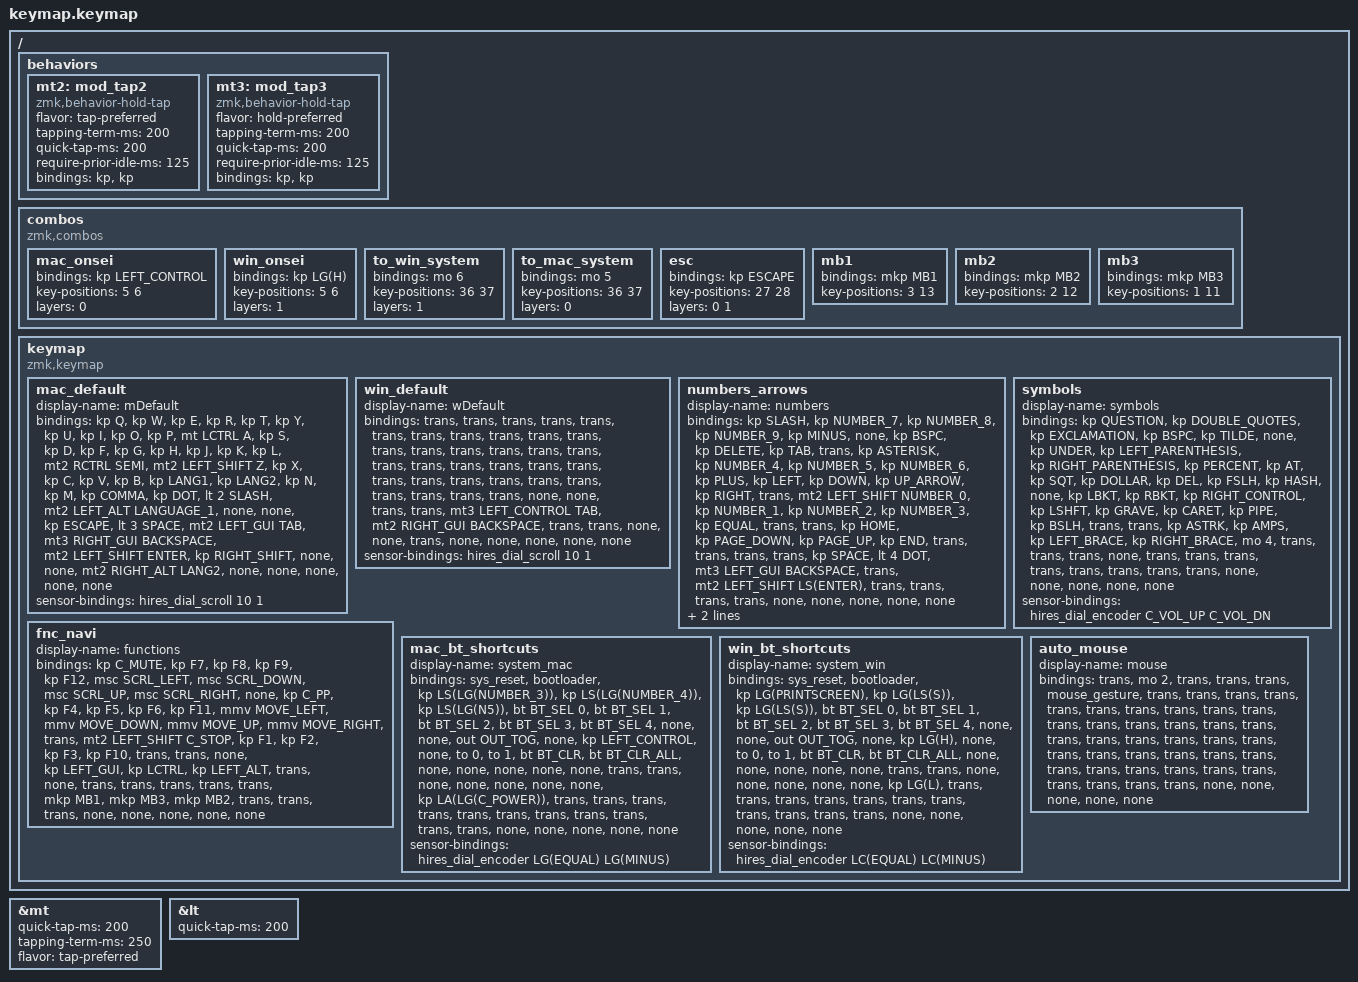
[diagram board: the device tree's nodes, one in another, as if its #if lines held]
/*
 * LisM キーマップを torabo-tsuki LP の S 配列へ移したもの。
 * 位置は size_s_transform の並び（上段10、中段10、下段12、親指12）。
 * 下段の内側2キー（B と N の間）は LisM に無いので &none。
 * ハイレゾダイヤルは LisM のエンコーダに対応する。
 */

#include <behaviors.dtsi>
#include <dt-bindings/zmk/bt.h>
#include <dt-bindings/zmk/keys.h>
#include <dt-bindings/zmk/outputs.h>
#include <dt-bindings/zmk/pointing.h>
#include <mouse-gesture.dtsi>

#if defined(TORABO_TSUKI_LP_INPUT_HIRES_DIAL)
#include <behaviors/hires_dial.dtsi>
#endif

&mt {
    quick-tap-ms = <200>;
    tapping-term-ms = <250>;
    flavor = "tap-preferred";
};

&lt { quick-tap-ms = <200>; };

/ {
    behaviors {
        mt2: mod_tap2 {
            compatible = "zmk,behavior-hold-tap";
            #binding-cells = <2>;
            flavor = "tap-preferred";
            tapping-term-ms = <200>;
            quick-tap-ms = <200>;
            require-prior-idle-ms = <125>;
            bindings = <&kp>, <&kp>;
        };

        mt3: mod_tap3 {
            compatible = "zmk,behavior-hold-tap";
            #binding-cells = <2>;
            flavor = "hold-preferred";
            tapping-term-ms = <200>;
            quick-tap-ms = <200>;
            require-prior-idle-ms = <125>;
            bindings = <&kp>, <&kp>;
        };
    };

    combos {
        compatible = "zmk,combos";

        mac_onsei {
            bindings = <&kp LEFT_CONTROL>;
            key-positions = <5 6>;
            layers = <0>;
        };

        win_onsei {
            bindings = <&kp LG(H)>;
            key-positions = <5 6>;
            layers = <1>;
        };

        to_win_system {
            bindings = <&mo 6>;
            key-positions = <36 37>;
            layers = <1>;
        };

        to_mac_system {
            bindings = <&mo 5>;
            key-positions = <36 37>;
            layers = <0>;
        };

        esc {
            bindings = <&kp ESCAPE>;
            key-positions = <27 28>;
            layers = <0 1>;
        };

        mb1 {
            bindings = <&mkp MB1>;
            key-positions = <3 13>;
        };

        mb2 {
            bindings = <&mkp MB2>;
            key-positions = <2 12>;
        };

        mb3 {
            bindings = <&mkp MB3>;
            key-positions = <1 11>;
        };
    };

    keymap {
        compatible = "zmk,keymap";

        mac_default {
            display-name = "mDefault";
            bindings = <
&kp Q              &kp W  &kp E      &kp R      &kp T        &kp Y                 &kp U            &kp I      &kp O   &kp P
&mt LCTRL A        &kp S  &kp D      &kp F      &kp G        &kp H                 &kp J            &kp K      &kp L   &mt2 RCTRL SEMI
&mt2 LEFT_SHIFT Z  &kp X  &kp C      &kp V      &kp B        &kp LANG1             &kp LANG2         &kp N      &kp M   &kp COMMA  &kp DOT  &lt 2 SLASH
&mt2 LEFT_ALT LANGUAGE_1  &none  &none  &kp ESCAPE  &lt 3 SPACE  &mt2 LEFT_GUI TAB  &mt3 RIGHT_GUI BACKSPACE  &mt2 LEFT_SHIFT ENTER  &kp RIGHT_SHIFT  &none  &none  &mt2 RIGHT_ALT LANG2
#if defined(TORABO_TSUKI_LP_KSCAN_4_DIRECTION_SWITCH)
&none &none &none &none &none
#elif defined(TORABO_TSUKI_LP_INPUT_HIRES_DIAL)
&to 1
#endif
            >;
        };

        win_default {
            display-name = "wDefault";
            bindings = <
&trans  &trans  &trans  &trans  &trans   &trans  &trans  &trans  &trans  &trans
&trans  &trans  &trans  &trans  &trans   &trans  &trans  &trans  &trans  &trans
&trans  &trans  &trans  &trans  &trans   &trans  &trans  &trans  &trans  &trans  &trans  &trans
&trans  &none   &none   &trans  &trans   &mt3 LEFT_CONTROL TAB  &mt2 RIGHT_GUI BACKSPACE  &trans  &trans  &none  &none  &trans
#if defined(TORABO_TSUKI_LP_KSCAN_4_DIRECTION_SWITCH)
&none &none &none &none &none
#elif defined(TORABO_TSUKI_LP_INPUT_HIRES_DIAL)
&to 0
#endif
            >;
        };

        numbers_arrows {
            display-name = "numbers";
            bindings = <
&kp SLASH                 &kp NUMBER_7  &kp NUMBER_8  &kp NUMBER_9  &kp MINUS        &none      &kp BSPC       &kp DELETE    &kp TAB    &trans
&kp ASTERISK              &kp NUMBER_4  &kp NUMBER_5  &kp NUMBER_6  &kp PLUS         &kp LEFT   &kp DOWN       &kp UP_ARROW  &kp RIGHT  &trans
&mt2 LEFT_SHIFT NUMBER_0  &kp NUMBER_1  &kp NUMBER_2  &kp NUMBER_3  &kp EQUAL        &trans     &trans         &kp HOME      &kp PAGE_DOWN  &kp PAGE_UP  &kp END  &trans
&trans                    &trans        &trans        &kp SPACE     &lt 4 DOT        &mt3 LEFT_GUI BACKSPACE  &trans  &mt2 LEFT_SHIFT LS(ENTER)  &trans  &trans  &trans  &trans
#if defined(TORABO_TSUKI_LP_KSCAN_4_DIRECTION_SWITCH)
&none &none &none &none &none
#elif defined(TORABO_TSUKI_LP_INPUT_HIRES_DIAL)
&kp C_MUTE
#endif
            >;
        };

        symbols {
            display-name = "symbols";
            bindings = <
&kp QUESTION  &kp DOUBLE_QUOTES  &kp EXCLAMATION  &kp BSPC  &kp TILDE      &none     &kp UNDER  &kp LEFT_PARENTHESIS  &kp RIGHT_PARENTHESIS  &kp PERCENT
&kp AT        &kp SQT            &kp DOLLAR       &kp DEL   &kp FSLH       &kp HASH  &none      &kp LBKT              &kp RBKT   &kp RIGHT_CONTROL
&kp LSHFT     &kp GRAVE          &kp CARET        &kp PIPE  &kp BSLH       &trans    &trans     &kp ASTRK             &kp AMPS     &kp LEFT_BRACE  &kp RIGHT_BRACE  &mo 4
&trans        &trans             &trans           &none     &trans         &trans    &trans     &trans                &trans       &trans          &trans       &trans
#if defined(TORABO_TSUKI_LP_KSCAN_4_DIRECTION_SWITCH)
&none &none &none &none &none
#elif defined(TORABO_TSUKI_LP_INPUT_HIRES_DIAL)
&kp C_MUTE
#endif
            >;
        };

        fnc_navi {
            display-name = "functions";
            bindings = <
&kp C_MUTE              &kp F7  &kp F8  &kp F9  &kp F12      &msc SCRL_LEFT  &msc SCRL_DOWN  &msc SCRL_UP  &msc SCRL_RIGHT  &none
&kp C_PP                &kp F4  &kp F5  &kp F6  &kp F11      &mmv MOVE_LEFT  &mmv MOVE_DOWN  &mmv MOVE_UP  &mmv MOVE_RIGHT  &trans
&mt2 LEFT_SHIFT C_STOP  &kp F1  &kp F2  &kp F3  &kp F10      &trans          &trans          &none         &kp LEFT_GUI     &kp LCTRL  &kp LEFT_ALT  &trans
&none                   &trans  &trans  &trans  &trans       &trans          &mkp MB1        &mkp MB3      &mkp MB2         &trans     &trans        &trans
#if defined(TORABO_TSUKI_LP_KSCAN_4_DIRECTION_SWITCH)
&none &none &none &none &none
#elif defined(TORABO_TSUKI_LP_INPUT_HIRES_DIAL)
&none
#endif
            >;
        };

        mac_bt_shortcuts {
            display-name = "system_mac";
            bindings = <
&sys_reset           &bootloader  &kp LS(LG(NUMBER_3))  &kp LS(LG(NUMBER_4))  &kp LS(LG(N5))   &bt BT_SEL 0  &bt BT_SEL 1  &bt BT_SEL 2  &bt BT_SEL 3  &bt BT_SEL 4
&none                &none        &out OUT_TOG          &none                 &kp LEFT_CONTROL &none         &to 0         &to 1         &bt BT_CLR    &bt BT_CLR_ALL
&none                &none        &none                 &none                 &none            &trans        &trans        &none         &none         &none         &none  &none
&kp LA(LG(C_POWER))  &trans       &trans                &trans                &trans           &trans        &trans        &trans        &trans        &trans        &trans &trans
#if defined(TORABO_TSUKI_LP_KSCAN_4_DIRECTION_SWITCH)
&none &none &none &none &none
#elif defined(TORABO_TSUKI_LP_INPUT_HIRES_DIAL)
&none
#endif
            >;
        };

        win_bt_shortcuts {
            display-name = "system_win";
            bindings = <
&sys_reset  &bootloader  &kp LG(PRINTSCREEN)  &kp LG(LS(S))  &kp LG(LS(S))   &bt BT_SEL 0  &bt BT_SEL 1  &bt BT_SEL 2  &bt BT_SEL 3  &bt BT_SEL 4
&none       &none        &out OUT_TOG         &none          &kp LG(H)       &none         &to 0         &to 1         &bt BT_CLR    &bt BT_CLR_ALL
&none       &none        &none                &none          &none           &trans        &trans        &none         &none         &none         &none  &none
&kp LG(L)   &trans       &trans               &trans         &trans          &trans        &trans        &trans        &trans        &trans        &trans &trans
#if defined(TORABO_TSUKI_LP_KSCAN_4_DIRECTION_SWITCH)
&none &none &none &none &none
#elif defined(TORABO_TSUKI_LP_INPUT_HIRES_DIAL)
&none
#endif
            >;
        };

        auto_mouse {
            display-name = "mouse";
            bindings = <
&trans  &mo 2   &trans  &trans  &trans   &mouse_gesture  &trans  &trans  &trans  &trans
&trans  &trans  &trans  &trans  &trans   &trans          &trans  &trans  &trans  &trans
&trans  &trans  &trans  &trans  &trans   &trans          &trans  &trans  &trans  &trans  &trans  &trans
&trans  &trans  &trans  &trans  &trans   &trans          &trans  &trans  &trans  &trans  &trans  &trans
#if defined(TORABO_TSUKI_LP_KSCAN_4_DIRECTION_SWITCH)
&none &none &none &none &none
#elif defined(TORABO_TSUKI_LP_INPUT_HIRES_DIAL)
&none
#endif
            >;
        };
    };
};

#if defined(TORABO_TSUKI_LP_INPUT_HIRES_DIAL)
&{/keymap/mac_default} {
    sensor-bindings = <&hires_dial_scroll 10 1>;
};

&{/keymap/win_default} {
    sensor-bindings = <&hires_dial_scroll 10 1>;
};

&{/keymap/numbers_arrows} {
    sensor-bindings = <&hires_dial_encoder C_VOL_UP C_VOL_DN>;
};

&{/keymap/symbols} {
    sensor-bindings = <&hires_dial_encoder C_VOL_UP C_VOL_DN>;
};

&{/keymap/mac_bt_shortcuts} {
    sensor-bindings = <&hires_dial_encoder LG(EQUAL) LG(MINUS)>;
};

&{/keymap/win_bt_shortcuts} {
    sensor-bindings = <&hires_dial_encoder LC(EQUAL) LC(MINUS)>;
};
#endif
